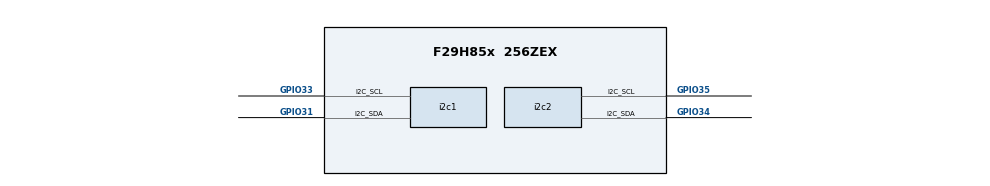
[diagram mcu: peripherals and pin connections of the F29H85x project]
/**
 * @cliArgs --device "F29H85x" --package "256ZEX" --part "F29H85x_256ZEX" --context "CPU1" --product "MCU_SDK_F29H85x@1.00.00.00"
 * @versions {"tool":"1.22.0+3877"}
 */

const divider15       = system.clockTree["PLL_REFDIV"];
divider15.divideValue = 1;

const multiplier1         = system.clockTree["PLL_IMULT"];
multiplier1.multiplyValue = 40;

const mux7       = system.clockTree["OSCCLKSRCSEL"];
mux7.inputSelect = "INTOSC2";

/**
 * Import the modules used in this configuration.
 */
const i2c  = scripting.addModule("/driverlib/i2c.js", {}, false);
const i2c1 = i2c.addInstance();
const i2c2 = i2c.addInstance();
const jtag = scripting.addModule("/driverlib/jtag.js");

/**
 * Write custom configuration values to the imported modules.
 */
i2c1.$name                  = "myI2C0";
i2c1.bitCount               = "I2C_BITCOUNT_8";
i2c1.dataCount              = 2;
i2c1.targetAddress          = 0x3C;
i2c1.txFifo                 = "I2C_FIFO_TX2";
i2c1.rxFifo                 = "I2C_FIFO_RX2";
i2c1.duty                   = "I2C_DUTYCYCLE_50";
i2c1.registerInterrupts     = true;
i2c1.enabledFIFOInterrupts  = ["I2C_INT_TXFF"];
i2c1.enabledInterrupts      = ["I2C_INT_STOP_CONDITION"];
i2c1.emulationMode          = "I2C_EMULATION_FREE_RUN";
i2c1.ownAddress             = 0x50;
i2c1.i2c.$assign            = "I2CA";
i2c1.i2c.i2c_sdaPin.$assign = "GPIO31";
i2c1.i2c.i2c_sclPin.$assign = "GPIO33";
i2c1.sdaQual.padConfig      = "PULLUP";
i2c1.sclQual.padConfig      = "PULLUP";
i2c1.periphClock.$name      = "driverlib_perClock0";
i2c1.periphConfig.$name     = "driverlib_perConfig0";

i2c2.$name                  = "myI2C1";
i2c2.mode                   = "TARGET";
i2c2.initialMode            = "RECEIVE_MODE";
i2c2.bitCount               = "I2C_BITCOUNT_8";
i2c2.dataCount              = 2;
i2c2.ownAddress             = 0x3C;
i2c2.emulationMode          = "I2C_EMULATION_FREE_RUN";
i2c2.registerInterrupts     = true;
i2c2.enabledFIFOInterrupts  = ["I2C_INT_RXFF"];
i2c2.txFifo                 = "I2C_FIFO_TX2";
i2c2.rxFifo                 = "I2C_FIFO_RX2";
i2c2.customModuleFrequency  = 7000000;
i2c2.targetAddress          = 0x50;
i2c2.enabledInterrupts      = ["I2C_INT_ADDR_TARGET","I2C_INT_ARB_LOST","I2C_INT_NO_ACK","I2C_INT_REG_ACCESS_RDY","I2C_INT_RX_DATA_RDY","I2C_INT_SCL_ECS","I2C_INT_STOP_CONDITION","I2C_INT_TX_DATA_RDY"];
i2c2.i2c.$assign            = "I2CB";
i2c2.i2c.i2c_sdaPin.$assign = "GPIO34";
i2c2.i2c.i2c_sclPin.$assign = "GPIO35";
i2c2.sdaQual.padConfig      = "PULLUP";
i2c2.sclQual.padConfig      = "PULLUP";
i2c2.periphClock.$name      = "driverlib_perClock1";
i2c2.periphConfig.$name     = "driverlib_perConfig1";
